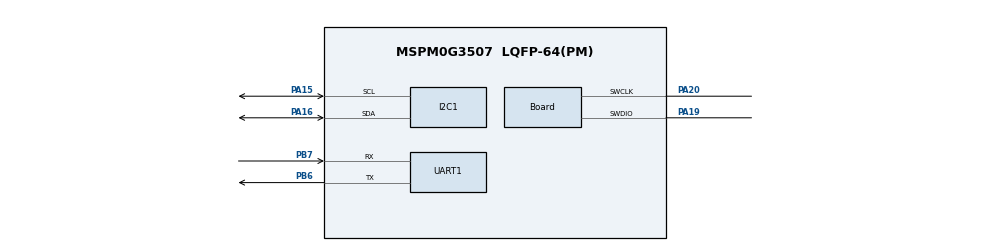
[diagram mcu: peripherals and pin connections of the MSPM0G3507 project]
/**
 * These arguments were used when this file was generated. They will be automatically applied on subsequent loads
 * via the GUI or CLI. Run CLI with '--help' for additional information on how to override these arguments.
 * @cliArgs --device "MSPM0G350X" --part "Default" --package "LQFP-64(PM)" --product "mspm0_sdk@2.11.00.07"
 * @v2CliArgs --device "MSPM0G3507" --package "LQFP-64(PM)" --product "mspm0_sdk@2.11.00.07"
 * @versions {"tool":"1.26.2+4477"}
 */

/**
 * Import the modules used in this configuration.
 */
const I2C           = scripting.addModule("/ti/driverlib/I2C", {}, false);
const I2C1          = I2C.addInstance();
const SYSCTL        = scripting.addModule("/ti/driverlib/SYSCTL");
const UART          = scripting.addModule("/ti/driverlib/UART", {}, false);
const UART1         = UART.addInstance();
const ProjectConfig = scripting.addModule("/ti/project_config/ProjectConfig");

/**
 * Write custom configuration values to the imported modules.
 */
I2C1.$name                     = "I2C_0";
I2C1.basicEnableController     = true;
I2C1.peripheral.$assign        = "I2C1";
I2C1.peripheral.sdaPin.$assign = "PA16";
I2C1.peripheral.sclPin.$assign = "PA15";
I2C1.sdaPinConfig.$name        = "ti_driverlib_gpio_GPIOPinGeneric0";
I2C1.sclPinConfig.$name        = "ti_driverlib_gpio_GPIOPinGeneric1";

const Board                       = scripting.addModule("/ti/driverlib/Board", {}, false);
Board.peripheral.$assign          = "DEBUGSS";
Board.peripheral.swclkPin.$assign = "PA20";
Board.peripheral.swdioPin.$assign = "PA19";

SYSCTL.clockTreeEn = true;

UART1.$name                            = "UART_2";
UART1.profile                          = "CONFIG_PROFILE_1";
UART1.peripheral.$assign               = "UART1";
UART1.targetBaudRate                   = 115200;
UART1.uartClkSrc                       = "BUSCLK";
UART1.ovsRate                          = "16";
UART1.enableFIFO                       = true;
UART1.enableInternalLoopback            = false;
UART1.peripheral.rxPin.$assign         = "PB7";
UART1.peripheral.txPin.$assign         = "PB6";
UART1.txPinConfig.$name                = "ti_driverlib_gpio_GPIOPinGeneric2";
UART1.txPinConfig.direction            = scripting.forceWrite("OUTPUT");
UART1.txPinConfig.hideOutputInversion  = scripting.forceWrite(false);
UART1.txPinConfig.onlyInternalResistor = scripting.forceWrite(false);
UART1.txPinConfig.passedPeripheralType = scripting.forceWrite("Digital");
UART1.rxPinConfig.$name                = "ti_driverlib_gpio_GPIOPinGeneric3";
UART1.rxPinConfig.hideOutputInversion  = scripting.forceWrite(false);
UART1.rxPinConfig.onlyInternalResistor = scripting.forceWrite(false);
UART1.rxPinConfig.passedPeripheralType = scripting.forceWrite("Digital");

ProjectConfig.deviceSpin = "MSPM0G3507";
ProjectConfig.stackSize   = 2048;
